VERSION "DNNBNNNYNNNNNNNNNNNNNNNNNNYYYNNNNNNNNNNNNN/4/%%%/4/'%**4NNN///"

NS_ :

BS_:

BU_: Engine Display Light

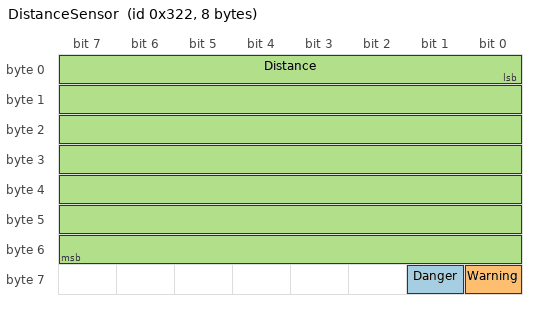
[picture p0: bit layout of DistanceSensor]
BO_ 802 DistanceSensor: 8 Vector__XXX
 SG_ Danger : 57|1@1+ (1,0) [0|0] "" Vector__XXX
 SG_ Warning : 56|1@1+ (1,0) [0|0] "" Vector__XXX
 SG_ Distance : 0|56@1+ (1,0) [0|0] "cm" Vector__XXX

BO_ 291 EngineState: 2 Engine
 SG_ EngineSpeed : 1|15@1- (1,0) [0|0] "rpm"  Display
 SG_ OnOff : 0|1@1+ (1,0) [0|0] ""  Display

BO_ 801 LightState: 1 Light
 SG_ FlashLight : 2|1@1+ (1,0) [0|1] ""  Display
 SG_ HeadLight : 0|1@1+ (1,0) [0|1] ""  Display

BA_DEF_ BU_  "ILUsed" ENUM  "Yes","No";
BA_DEF_ SG_  "GenSigSendType" ENUM  "Cyclic","OnWrite","OnWriteWithRepetition","OnChange","OnChangeWithRepetition","IfActive","IfActiveWithRepetition";
BA_DEF_ BO_  "GenMsgDelayTime" INT 1 1000;
BA_DEF_ BO_  "GenMsgCycleTime" INT 2 50000;
BA_DEF_ BO_  "GenMsgCycleTimeFast" INT 2 100000;
BA_DEF_ BO_  "GenMsgILSupport" ENUM  "No","Yes";
BA_DEF_ BU_  "NodeLayerModules" STRING ;
BA_DEF_DEF_  "ILUsed" "Yes";
BA_DEF_DEF_  "GenSigSendType" "Cyclic";
BA_DEF_DEF_  "GenMsgDelayTime" 1;
BA_DEF_DEF_  "GenMsgCycleTime" 2;
BA_DEF_DEF_  "GenMsgCycleTimeFast" 100;
BA_DEF_DEF_  "GenMsgILSupport" "Yes";
BA_DEF_DEF_  "NodeLayerModules" "CANoeILNLVector.dll";
BA_ "GenMsgCycleTime" BO_ 291 100;
BA_ "GenMsgCycleTime" BO_ 801 100;
BA_ "GenSigSendType" SG_ 801 HeadLight 3;
VAL_ 291 OnOff 1 "On" 0 "Off" ;
